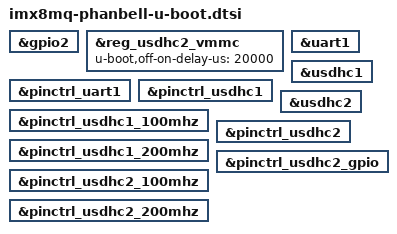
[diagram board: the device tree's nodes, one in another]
// SPDX-License-Identifier: (GPL-2.0 OR MIT)

#include "imx8mq-u-boot.dtsi"

&gpio2 {
	bootph-pre-ram;
};

&reg_usdhc2_vmmc {
	bootph-pre-ram;
	u-boot,off-on-delay-us = <20000>;
};

&uart1 {
	bootph-pre-ram;
};

&pinctrl_uart1 {
	bootph-pre-ram;
};

&usdhc1 {
	bootph-pre-ram;
};

&pinctrl_usdhc1 {
	bootph-pre-ram;
};

&pinctrl_usdhc1_100mhz {
	bootph-pre-ram;
};

&pinctrl_usdhc1_200mhz {
	bootph-pre-ram;
};

&usdhc2 {
	bootph-pre-ram;
};

&pinctrl_usdhc2 {
	bootph-pre-ram;
};

&pinctrl_usdhc2_100mhz {
	bootph-pre-ram;
};

&pinctrl_usdhc2_200mhz {
	bootph-pre-ram;
};

&pinctrl_usdhc2_gpio {
	bootph-pre-ram;
};
